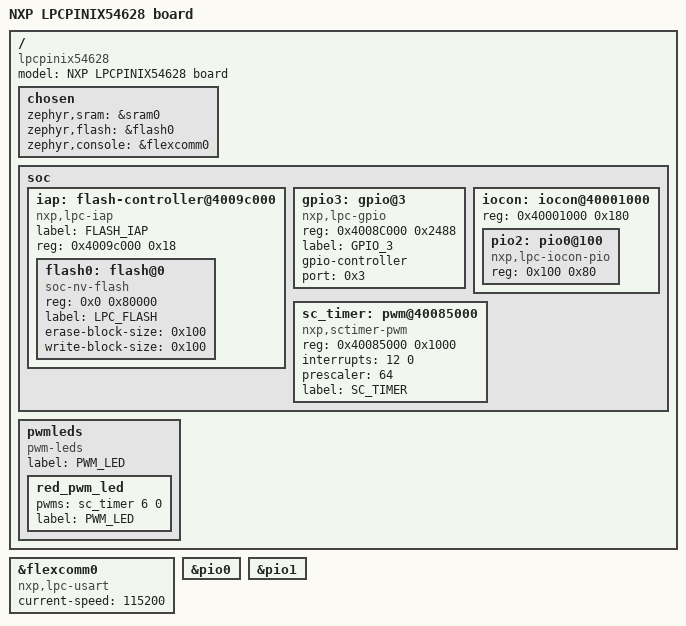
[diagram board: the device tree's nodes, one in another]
/*
 * Copyright (c) 2020 Seagate Technology LLC
 *
 * SPDX-License-Identifier: Apache-2.0
 */

/dts-v1/;

#include <nxp/nxp_lpc54xxx_m4.dtsi>

/ {
	model = "NXP LPCPINIX54628 board";
	compatible = "lpcpinix54628", "nxp,lpc";
	chosen {
		zephyr,sram = &sram0;
		zephyr,flash = &flash0;
		zephyr,console = &flexcomm0;
	};

	soc {
		
		iap: flash-controller@4009c000 {
			compatible = "nxp,lpc-iap";
			label = "FLASH_IAP";
			reg = < 0x4009c000 0x18 >;
			#address-cells = < 0x1 >;
			#size-cells = < 0x1 >;
			flash0: flash@0 {
				compatible = "soc-nv-flash";
				reg = < 0x0 0x80000 >;
				label = "LPC_FLASH";
				erase-block-size = < 0x100 >;
				write-block-size = < 0x100 >;
			};
		};
		gpio3: gpio@3 {
			compatible = "nxp,lpc-gpio";
			reg = <0x4008C000 0x2488>;

			label = "GPIO_3";
			gpio-controller;
			#gpio-cells = <2>;
			port = <0x3>;

			status = "okay";
		};

		iocon: iocon@40001000 {
			reg = < 0x40001000 0x180>;
			ranges = <0x0 0x40001000 0x180>;
			pio2: pio0@100 {
				compatible = "nxp,lpc-iocon-pio";
				reg = <0x100 0x80>;
				status = "okay";
			};
		};

		sc_timer: pwm@40085000 {
			compatible = "nxp,sctimer-pwm";
			reg = <0x40085000 0x1000>;
			interrupts = <12 0>;
			status = "okay";
			prescaler = <64>;
			label = "SC_TIMER";
			#pwm-cells = <2>;
		};
	};

	pwmleds {
		compatible = "pwm-leds";
		label = "PWM_LED";
		red_pwm_led: red_pwm_led {
			pwms = <&sc_timer 6 0>;
			label = "PWM_LED";
			status = "okay";
		};
	};

};

&flexcomm0 {
	compatible = "nxp,lpc-usart";
	current-speed = <115200>;
	status = "okay";
};

&pio0 {
	status = "okay";
};

&pio1 {
	status = "okay";
};
